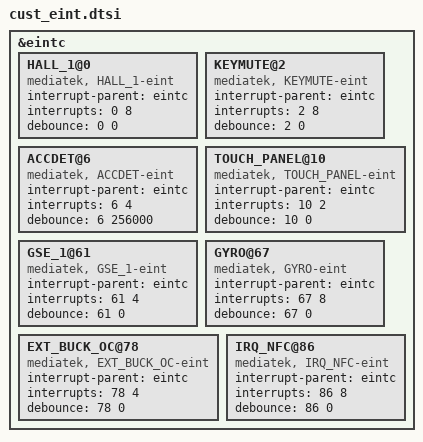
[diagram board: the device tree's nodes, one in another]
/*
 * Generated by MTK SP DrvGen Version 03.13.6 for MT6735M. Copyright MediaTek Inc. (C) 2013.
 * Fri Jun 12 17:47:08 2015
 * Do Not Modify the File.
 */

/*************************
 * EINT DTSI File
*************************/

&eintc {
	HALL_1@0 {
		compatible = "mediatek, HALL_1-eint";
		interrupt-parent = <&eintc>;
		interrupts = <0 8>;
		debounce = <0 0>;
	};

	KEYMUTE@2 {
		compatible = "mediatek, KEYMUTE-eint";
		interrupt-parent = <&eintc>;
		interrupts = <2 8>;
		debounce = <2 0>;
	};

	ACCDET@6 {
		compatible = "mediatek, ACCDET-eint";
		interrupt-parent = <&eintc>;
		interrupts = <6 4>;
		debounce = <6 256000>;
	};

	TOUCH_PANEL@10 {
		compatible = "mediatek, TOUCH_PANEL-eint";
		interrupt-parent = <&eintc>;
		interrupts = <10 2>;
		debounce = <10 0>;
	};

	GSE_1@61 {
		compatible = "mediatek, GSE_1-eint";
		interrupt-parent = <&eintc>;
		interrupts = <61 4>;
		debounce = <61 0>;
	};

	GYRO@67 {
		compatible = "mediatek, GYRO-eint";
		interrupt-parent = <&eintc>;
		interrupts = <67 8>;
		debounce = <67 0>;
	};

	EXT_BUCK_OC@78 {
		compatible = "mediatek, EXT_BUCK_OC-eint";
		interrupt-parent = <&eintc>;
		interrupts = <78 4>;
		debounce = <78 0>;
	};

	IRQ_NFC@86 {
		compatible = "mediatek, IRQ_NFC-eint";
		interrupt-parent = <&eintc>;
		interrupts = <86 8>;
		debounce = <86 0>;
	};

};
